# I2C0_1.0 register map
Vendor: Texas Instruments
Peripheral module from a debugger description file (folder mspm0h321x).
Registers are 32-bit, read-write, no defined reset value unless marked. A register's access mark holds for its fields unless they carry their own. Offsets are as the file gives them; lines under a group give offsets from that group; [hi:lo] are bit positions; {n}, {i} and the like mark numbered series; 'fields as' and 'values as' point back to an identical list; <NAME> marks a mode.

## I2C0 (part 1 of 2)
0x800 I2C0_GPRCM group
  0x00 I2C0_PWREN — Power enable
    [0] ENABLE — Enable the power
      0=DISABLE (Disable Power); 1=ENABLE (Enable Power)
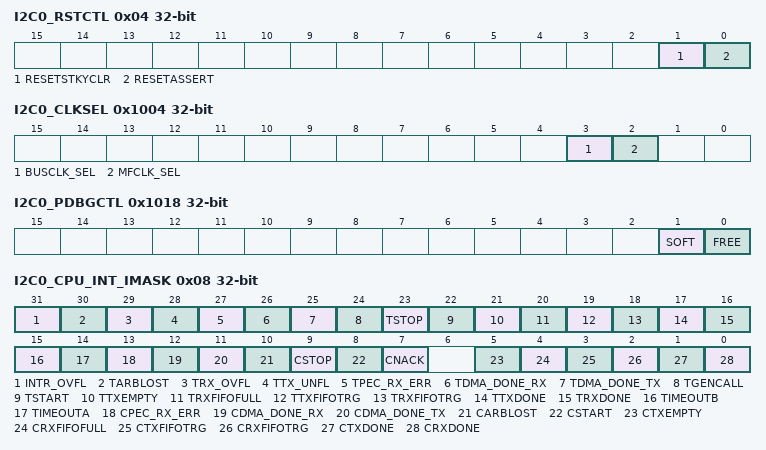
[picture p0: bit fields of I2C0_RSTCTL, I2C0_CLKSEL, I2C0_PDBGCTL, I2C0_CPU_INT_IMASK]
  0x04 I2C0_RSTCTL — Reset Control
    [1] RESETSTKYCLR — Clear the RESETSTKY bit in the STAT register
      0=NOP (Writing 0 has no effect); 1=CLR (Clear reset sticky bit)
    [0] RESETASSERT — Assert reset to the peripheral
      0=NOP (Writing 0 has no effect); 1=ASSERT (Assert reset)
  0x08 I2C0_CLKCFG — Peripheral Clock Configuration Register
    [8] BLOCKASYNC — Async Clock Request is blocked from starting SYSOSC or forcing bus clock to 32MHz
      0=DISABLE (Not block async clock request); 1=ENABLE (Block async clock request)
  0x14 I2C0_STAT ro — Status Register
    [16] RESETSTKY — This bit indicates, if the peripheral was reset, since this bit was cleared by RESETSTKYCLR in the RSTCTL register
      0=NORES (The peripheral has not been reset since this bit was last cleared by RESETSTKYCLR in the RSTCTL register); 1=RESET (The peripheral was reset since the last bit clear)
0x1000 I2C0_CLKDIV — Clock Divider
  [2:0] RATIO — Selects divide ratio of module clock
    0=DIV_BY_1 (Do not divide clock source); {v}=DIV_BY_{v+1} (Divide clock source by {v+1}) (v=1..7)
0x1004 I2C0_CLKSEL — Clock Select for Ultra Low Power peripherals
  [3] BUSCLK_SEL — Selects BUSCLK as clock source if enabled
    0=DISABLE (Does not select this clock as a source); 1=ENABLE (Select this clock as a source)
  [2] MFCLK_SEL — Selects MFCLK as clock source if enabled
    values as BUSCLK_SEL
0x1018 I2C0_PDBGCTL — Peripheral Debug Control
  [1] SOFT — Soft halt boundary control. This function is only available, if [FREE] is set to 'STOP'
    0=IMMEDIATE (The peripheral will halt immediately, even if the resultant state will result in corruption if the system is restarted); 1=DELAYED (The peripheral blocks the debug freeze until it has reached a boundary where it can resume without corruption)
  [0] FREE — Free run control
    0=STOP (The peripheral freezes functionality while the Core Halted input is asserted and resumes when it is deasserted.); 1=RUN (The peripheral ignores the state of the Core Halted input)
0x1020 I2C0_CPU_INT group
  0x00 I2C0_CPU_INT_IIDX ro — Interrupt index
    [7:0] STAT — I2C Module Interrupt Vector Value. This register provides the highes priority interrupt index. A read clears the corresponding interrupt flag in RIS and MISC. 15h-1Fh = Reserved
      0=NO_INTR (No interrupt pending); 1=CRXDONEFG (Controller data received); 2=CTXDONEFG (Controller data transmitted); 3=CRXFIFOTRG (Controller receive FIFO Trigger Level); 4=CTXFIFOTRG (Controller transmit FIFO Trigger level); 5=CRXFIFOFULL (RX FIFO FULL Event/interrupt pending); 6=CTX_EMPTY (Transmit FIFO/Buffer Empty Event/interrupt pending); 8=CNACKFG (Address/Data NACK); 9=CSTARTFG (Start Event); 10=CSTOPFG (Stop Event); 11=CARBLOSTFG (Arbitration Lost); 12=CDMA_DONE_TX (DMA DONE on Channel TX); 13=CDMA_DONE_RX (DMA DONE on Channel RX); 14=CPEC_RX_ERR (Controller PEC Receive Error Event); 15=TIMEOUTA (Timeout A Event); 16=TIMEOUTB (Timeout B Event); 17=TRXDONEFG (Target Data Event); 18=TTXDONEFG (Target Data Event); 19=TRXFIFOTRG (Target receive FIFO Trigger Level); 20=TTXFIFOTRG (Target transmit FIFO Trigger level); 21=TRXFIFOFULL (RX FIFO FULL Event/interrupt pending); 22=TTXEMPTY (Transmit FIFO/Buffer Empty Event/interrupt pending); 23=TSTARTFG (Start Event); 24=TSTOPFG (Stop Event); 25=TGENCALL (General Call Event); 26=TDMA_DONE_TX (DMA DONE on Channel TX); 27=TDMA_DONE_RX (DMA DONE on Channel RX); 28=TPEC_RX_ERR (Target PEC receive error event); 29=TTX_UNFL (Target TX FIFO underflow); 30=TRX_OVFL (Target RX FIFO overflow event); 31=TARBLOST (Target arbitration lost event); 32=INTR_OVFL (Interrupt overflow event)
  0x08 I2C0_CPU_INT_IMASK — Interrupt mask
    [31] INTR_OVFL — Interrupt Overflow Interrupt Mask
      0=CLR (Clear Interrupt Mask); 1=SET (Set Interrupt Mask)
    [30] TARBLOST — Target Arbitration Lost
      0=CLR (Clear Set Interrupt Mask); 1=SET (Set Interrupt Mask)
    [29] TRX_OVFL — Target RX FIFO overflow
      0=CLR (Clear Interrupt Mask); 1=SET (Set Interrupt Mask)
    [28] TTX_UNFL — Target TX FIFO underflow
      0=CLR (Clear Interrupt Mask); 1=SET (Set Interrupt Mask)
    [27] TPEC_RX_ERR — Target RX Pec Error Interrupt
      0=CLR (Clear Interrupt Mask); 1=SET (Set Interrupt Mask)
    [26] TDMA_DONE_RX — Target DMA Done on Event Channel RX
      0=CLR (Clear Interrupt Mask); 1=SET (Set Interrupt Mask)
    [25] TDMA_DONE_TX — Target DMA Done on Event Channel TX
      0=CLR (Clear Interrupt Mask); 1=SET (Set Interrupt Mask)
    [24] TGENCALL — General Call Interrupt
      0=CLR (Clear Interrupt Mask); 1=SET (Set Interrupt Mask)
    [23] TSTOP — Stop Condition Interrupt
      0=CLR (Clear Interrupt Mask); 1=SET (Set Interrupt Mask)
    [22] TSTART — Start Condition Interrupt
      0=CLR (Clear Interrupt Mask); 1=SET (Set Interrupt Mask)
    [21] TTXEMPTY — Target Transmit FIFO Empty interrupt mask. This interrupt is set if all data in the Transmit FIFO have been shifted out and the transmit goes into idle mode.
      0=CLR (Clear Interrupt Mask); 1=SET (Set Interrupt Mask)
    [20] TRXFIFOFULL — RXFIFO full event. This interrupt is set if an Target RX FIFO is full.
      0=CLR (Clear Interrupt Mask); 1=SET (Set Interrupt Mask)
    [19] TTXFIFOTRG — Target Transmit FIFO Trigger
      0=CLR (Clear Interrupt Mask); 1=SET (Set Interrupt Mask)
    [18] TRXFIFOTRG — Target Receive FIFO Trigger
      0=CLR (Clear Interrupt Mask); 1=SET (Set Interrupt Mask)
    [17] TTXDONE — Target Transmit Transaction completed Interrupt
      0=CLR (Clear Interrupt Mask); 1=SET (Set Interrupt Mask)
    [16] TRXDONE — Target Receive Data Interrupt Signals that a byte has been received
      0=CLR (Clear Interrupt Mask); 1=SET (Set Interrupt Mask)
    [15] TIMEOUTB — Timeout B Interrupt
      0=CLR (Clear Interrupt Mask); 1=SET (Set Interrupt Mask)
    [14] TIMEOUTA — Timeout A Interrupt
      0=CLR (Clear Interrupt Mask); 1=SET (Set Interrupt Mask)
    [13] CPEC_RX_ERR — Controller RX Pec Error Interrupt
      0=CLR (Clear Interrupt Mask); 1=SET (Set Interrupt Mask)
    [12] CDMA_DONE_RX — DMA Done on Event Channel RX
      0=CLR (Interrupt disabled); 1=SET (Set Interrupt Mask)
    [11] CDMA_DONE_TX — DMA Done on Event Channel TX
      0=CLR (Interrupt disabled); 1=SET (Set Interrupt Mask)
    [10] CARBLOST — Arbitration Lost Interrupt
      0=CLR (Clear Interrupt Mask); 1=SET (Set Interrupt Mask)
    [9] CSTOP — STOP Detection Interrupt
      0=CLR (Clear Interrupt Mask); 1=SET (Set Interrupt Mask)
    [8] CSTART — START Detection Interrupt
      0=CLR (Clear Interrupt Mask); 1=SET (Set Interrupt Mask)
    [7] CNACK — Address/Data NACK Interrupt
      0=CLR (Clear Interrupt Mask); 1=SET (Set Interrupt Mask)
    [5] CTXEMPTY — Transmit FIFO Empty interrupt mask. This interrupt is set if all data in the Transmit FIFO have been shifted out and the transmit goes into idle mode.
      0=CLR (Clear Interrupt Mask); 1=SET (Set Interrupt Mask)
    [4] CRXFIFOFULL — RXFIFO full event. This interrupt is set if an RX FIFO is full.
      0=CLR (Clear Interrupt Mask); 1=SET (Set Interrupt Mask)
    [3] CTXFIFOTRG — Controller Transmit FIFO Trigger Trigger when Transmit FIFO contains <= defined bytes
      0=CLR (Clear Interrupt Mask); 1=SET (Set Interrupt Mask)
    [2] CRXFIFOTRG — Controller Receive FIFO Trigger Trigger when RX FIFO contains >= defined bytes
      0=CLR (Clear Interrupt Mask); 1=SET (Set Interrupt Mask)
    [1] CTXDONE — Controller Transmit Transaction completed Interrupt
      0=CLR (Clear Interrupt Mask); 1=SET (Set Interrupt Mask)
    [0] CRXDONE — Controller Receive Transaction completed Interrupt
      0=CLR (Clear Interrupt Mask); 1=SET (Set Interrupt Mask)
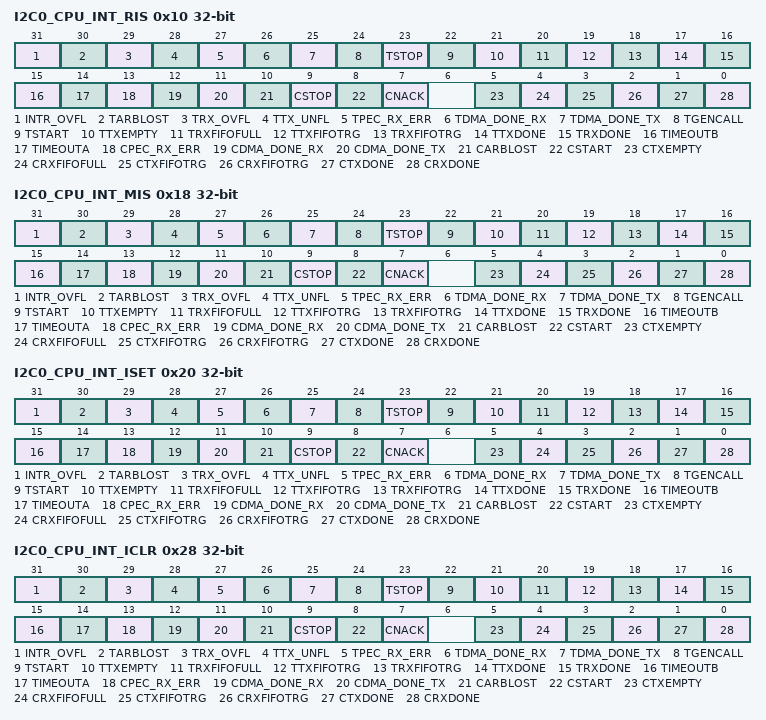
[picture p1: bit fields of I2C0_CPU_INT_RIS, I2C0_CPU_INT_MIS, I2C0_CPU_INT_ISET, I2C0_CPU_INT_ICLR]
  0x10 I2C0_CPU_INT_RIS — Raw interrupt status
    [31] INTR_OVFL — Interrupt overflow interrupt It is set when CSTART or CSTOP interrupts overflow i.e. occur twice without being serviced
      0=CLR (Interrupt did not occur); 1=SET (Interrupt occured)
    [30] TARBLOST — Target Arbitration Lost
      0=CLR (Interrupt did not occur); 1=SET (Interrupt occured)
    [29] TRX_OVFL — Target RX FIFO overflow
      0=CLR (Interrupt did not occur); 1=SET (Interrupt Occured)
    [28] TTX_UNFL — Target TX FIFO underflow
      0=CLR (Interrupt did not occur); 1=SET (Interrupt occured)
    [27] TPEC_RX_ERR — Target RX Pec Error Interrupt
      0=CLR (Interrupt did not occur); 1=SET (Interrupt ocuured)
    [26] TDMA_DONE_RX — DMA Done on Event Channel RX
      0=CLR (Clear interrupt); 1=SET (Set interrupt)
    [25] TDMA_DONE_TX — DMA Done on Event Channel TX
      0=CLR (Clear interrupt); 1=SET (Set interrupt)
    [24] TGENCALL — General Call Interrupt
      0=CLR (Clear Interrupt Mask); 1=SET (Interrupt occured)
    [23] TSTOP — Stop Condition Interrupt
      0=CLR (Clear Interrupt); 1=SET (Set interrupt)
    [22] TSTART — Start Condition Interrupt
      0=CLR (Clear interrupt); 1=SET (Set Interrupt)
    [21] TTXEMPTY — Transmit FIFO Empty interrupt mask. This interrupt is set if all data in the Transmit FIFO have been shifted out and the transmit goes into idle mode.
      0=CLR (Interrupt did not occur); 1=SET (Interrupt occured)
    [20] TRXFIFOFULL — RXFIFO full event. This interrupt is set if an RX FIFO is full.
      0=CLR (Clear Interrupt Mask); 1=SET (Interrupt occured)
    [19] TTXFIFOTRG — Target Transmit FIFO Trigger
      0=CLR (Clear Interrupt Mask); 1=SET (Interrupt occured)
    [18] TRXFIFOTRG — Target Receive FIFO Trigger
      0=CLR (Clear Interrupt Mask); 1=SET (Interrupt occured)
    [17] TTXDONE — Target Transmit Transaction completed Interrupt
      0=CLR (Interrupt did not occur); 1=SET (Interrupt occured)
    [16] TRXDONE — Target Receive Data Interrupt Signals that a byte has been received
      0=CLR (Interrupt did not occur); 1=SET (Interrupt occured)
    [15] TIMEOUTB — Timeout B Interrupt
      0=CLR (Interrupt did not occur); 1=SET (Interrupt occured)
    [14] TIMEOUTA — Timeout A Interrupt
      0=CLR (Interrupt did not occur); 1=SET (Interrupt occured)
    [13] CPEC_RX_ERR — Controller RX Pec Error Interrupt
      0=CLR (Interrupt did not occur); 1=SET (Interrupt Occured)
    [12] CDMA_DONE_RX — DMA Done on Event Channel RX
      0=CLR (Interrupt disabled); 1=SET (Interrupt occured)
    [11] CDMA_DONE_TX — DMA Done on Event Channel TX
      0=CLR (Interrupt disabled); 1=SET (Interrupt occured)
    [10] CARBLOST — Arbitration Lost Interrupt
      0=CLR (Interrupt did not occur); 1=SET (Interrupt occured)
    [9] CSTOP — STOP Detection Interrupt
      0=CLR (Interrupt did not occur); 1=SET (Interrupt occured)
    [8] CSTART — START Detection Interrupt
      0=CLR (Interrupt did not occur); 1=SET (Interrupt occured)
    [7] CNACK — Address/Data NACK Interrupt
      0=CLR (Interrupt did not occur); 1=SET (Interrupt occured)
    [5] CTXEMPTY — Transmit FIFO Empty interrupt mask. This interrupt is set if all data in the Transmit FIFO have been shifted out and the transmit goes into idle mode.
      0=CLR (Interrupt did not occur); 1=SET (Interrupt occured)
    [4] CRXFIFOFULL — RXFIFO full event. This interrupt is set if an RX FIFO is full.
      0=CLR (Interrupt did not occur); 1=SET (Interrupt occured)
    [3] CTXFIFOTRG — Controller Transmit FIFO Trigger Trigger when Transmit FIFO contains <= defined bytes
      0=CLR (Clear Interrupt Mask); 1=SET (Interrupt occured)
    [2] CRXFIFOTRG — Controller Receive FIFO Trigger Trigger when RX FIFO contains >= defined bytes
      0=CLR (Clear Interrupt Mask); 1=SET (Interrupt occured)
    [1] CTXDONE — Controller Transmit Transaction completed Interrupt
      0=CLR (Interrupt did not occur); 1=SET (Interrupt occured)
    [0] CRXDONE — Controller Receive Transaction completed Interrupt
      0=CLR (Interrupt did not occur); 1=SET (Interrupt occured)
  0x18 I2C0_CPU_INT_MIS — Masked interrupt status
    [31] INTR_OVFL — Interrupt overflow
      0=CLR (Interrupt did not occur); 1=SET (Interrupt occured)
    [30] TARBLOST — Target Arbitration Lost
      0=CLR (Clear interrupt mask); 1=SET (Set interrupt mask)
    [29] TRX_OVFL — Target RX FIFO overflow
      0=CLR (Clear interrupt mask); 1=SET (Set interrupt mask)
    [28] TTX_UNFL — Target TX FIFO underflow
      0=CLR (Clear interrupt mask); 1=SET (Set interrupt mask)
    [27] TPEC_RX_ERR — Target RX Pec Error Interrupt
      0=CLR (Clear interrupt mask); 1=SET (Set interrupt mask)
    [26] TDMA_DONE_RX — DMA Done on Event Channel RX
      0=CLR (Clear MIS); 1=SET (Set MIS)
    [25] TDMA_DONE_TX — DMA Done on Event Channel TX
      0=CLR (Clear MIS); 1=SET (Set MIS)
    [24] TGENCALL — General Call Interrupt
      0=CLR (Interrupt did not occur); 1=SET (Interrupt occured)
    [23] TSTOP — Target STOP Detection Interrupt
      0=CLR (Clear MIS); 1=SET (Set MIS)
    [22] TSTART — Target START Detection Interrupt
      0=CLR (Clear MIS); 1=SET (Set MIS)
    [21] TTXEMPTY — Transmit FIFO Empty interrupt mask. This interrupt is set if all data in the Transmit FIFO have been shifted out and the transmit goes into idle mode.
      0=CLR (Interrupt did not occur); 1=SET (Interrupt occured)
    [20] TRXFIFOFULL — RXFIFO full event. This interrupt is set if an RX FIFO is full.
      0=CLR (Clear Interrupt Mask); 1=SET (Interrupt occured)
    [19] TTXFIFOTRG — Target Transmit FIFO Trigger
      0=CLR (Clear Interrupt Mask); 1=SET (Interrupt occured)
    [18] TRXFIFOTRG — Target Receive FIFO Trigger
      0=CLR (Clear Interrupt Mask); 1=SET (Interrupt occured)
    [17] TTXDONE — Target Transmit Transaction completed Interrupt
      0=CLR (Interrupt did not occur); 1=SET (Interrupt occured)
    [16] TRXDONE — Target Receive Data Interrupt Signals that a byte has been received
      0=CLR (Interrupt did not occur); 1=SET (Interrupt occured)
    [15] TIMEOUTB — Timeout B Interrupt
      0=CLR (Clear interrupt mask); 1=SET (Set interrupt mask)
    [14] TIMEOUTA — Timeout A Interrupt
      0=CLR (Interrupt did not occur); 1=SET (Interrupt occured)
    [13] CPEC_RX_ERR — Controller RX Pec Error Interrupt
      0=CLR (Clear interrupt mask); 1=SET (Set interrupt mask)
    [12] CDMA_DONE_RX — DMA Done on Event Channel RX
      0=CLR (Interrupt disabled); 1=SET (Interrupt occured)
    [11] CDMA_DONE_TX — DMA Done on Event Channel TX
      0=CLR (Interrupt disabled); 1=SET (Interrupt occured)
    [10] CARBLOST — Arbitration Lost Interrupt
      0=CLR (Interrupt did not occur); 1=SET (Interrupt occured)
    [9] CSTOP — STOP Detection Interrupt
      0=CLR (Interrupt did not occur); 1=SET (Interrupt occured)
    [8] CSTART — START Detection Interrupt
      0=CLR (Interrupt did not occur); 1=SET (Interrupt occured)
    [7] CNACK — Address/Data NACK Interrupt
      0=CLR (Interrupt did not occur); 1=SET (Interrupt occured)
    [5] CTXEMPTY — Transmit FIFO Empty interrupt mask. This interrupt is set if all data in the Transmit FIFO have been shifted out and the transmit goes into idle mode.
      0=CLR (Interrupt did not occur); 1=SET (Interrupt occured)
    [4] CRXFIFOFULL — RXFIFO full event. This interrupt is set if the RX FIFO is full.
      0=CLR (Interrupt did not occur); 1=SET (Interrupt occured)
    [3] CTXFIFOTRG — Controller Transmit FIFO Trigger Trigger when Transmit FIFO contains <= defined bytes
      0=CLR (Clear Interrupt Mask); 1=SET (Interrupt occured)
    [2] CRXFIFOTRG — Controller Receive FIFO Trigger Trigger when RX FIFO contains >= defined bytes
      0=CLR (Clear Interrupt Mask); 1=SET (Interrupt occured)
    [1] CTXDONE — Controller Transmit Transaction completed Interrupt
      0=CLR (Interrupt did not occur); 1=SET (Interrupt occured)
    [0] CRXDONE — Controller Receive Data Interrupt
      0=CLR (Interrupt did not occur); 1=SET (Interrupt occured)
  0x20 I2C0_CPU_INT_ISET — Interrupt set
    [31] INTR_OVFL — Interrupt overflow
      0=NO_EFFECT; 1=SET (Set interrupt)
    [30] TARBLOST — Target Arbitration Lost
      0=NO_EFFECT (Writing 0 has no effect); 1=SET (Set interrupt)
    [29] TRX_OVFL — Target RX FIFO overflow
      0=NO_EFFECT (Writing 0 has no effect); 1=SET (Set interrupt)
    [28] TTX_UNFL — Target TX FIFO underflow
      0=NO_EFFECT (Writing 0 has no effect); 1=SET (Set interrupt)
    [27] TPEC_RX_ERR — Target RX Pec Error Interrupt
      0=NO_EFFECT (Writing 0 has no effect); 1=SET (Set interrupt)
    [26] TDMA_DONE_RX — DMA Done on Event Channel RX
      0=NO_EFFECT (Writing 0 has no effect); 1=SET (Set interrupt)
    [25] TDMA_DONE_TX — DMA Done on Event Channel TX
      0=NO_EFFECT (Writing 0 has no effect); 1=SET (Set interrupt)
    [24] TGENCALL — General Call Interrupt
      0=NO_EFFECT (Writing 0 has no effect); 1=SET (Set Interrupt)
    [23] TSTOP — Stop Condition Interrupt
      0=NO_EFFECT (Writing 0 has no effect); 1=SET (Set interrupt)
    [22] TSTART — Start Condition Interrupt
      0=NO_EFFECT (Writing 0 has no effect); 1=SET (Set interrupt)
    [21] TTXEMPTY — Transmit FIFO Empty interrupt mask. This interrupt is set if all data in the Transmit FIFO have been shifted out and the transmit goes into idle mode.
      0=NO_EFFECT (Writing 0 has no effect); 1=SET (Set Interrupt)
    [20] TRXFIFOFULL — RXFIFO full event. This interrupt is set if an RX FIFO is full.
      0=NO_EFFECT (Clear Interrupt Mask); 1=SET (Set Interrupt)
    [19] TTXFIFOTRG — Target Transmit FIFO Trigger
      0=NO_EFFECT (Clear Interrupt Mask); 1=SET (Set Interrupt)
    [18] TRXFIFOTRG — Target Receive FIFO Trigger
      0=NO_EFFECT (Clear Interrupt Mask); 1=SET (Set Interrupt)
    [17] TTXDONE — Target Transmit Transaction completed Interrupt
      0=NO_EFFECT (Writing 0 has no effect); 1=SET (Set Interrupt)
    [16] TRXDONE — Target Receive Data Interrupt Signals that a byte has been received
      0=NO_EFFECT (Writing 0 has no effect); 1=SET (Set Interrupt)
    [15] TIMEOUTB — Timeout B Interrupt
      0=NO_EFFECT (Writing 0 has no effect); 1=SET (Set interrupt)
    [14] TIMEOUTA — Timeout A interrupt
      0=NO_EFFECT (Writing 0 has no effect); 1=SET (Set Interrupt)
    [13] CPEC_RX_ERR — Controller RX Pec Error Interrupt
      0=NO_EFFECT (Writing 0 has no effect); 1=SET (Set interrupt)
    [12] CDMA_DONE_RX — DMA Done on Event Channel RX
      0=NO_EFFECT (Interrupt disabled); 1=SET (Set Interrupt)
    [11] CDMA_DONE_TX — DMA Done on Event Channel TX
      0=NO_EFFECT (Interrupt disabled); 1=SET (Set Interrupt)
    [10] CARBLOST — Arbitration Lost Interrupt
      0=NO_EFFECT (Writing 0 has no effect); 1=SET (Set Interrupt)
    [9] CSTOP — STOP Detection Interrupt
      0=NO_EFFECT (Writing 0 has no effect); 1=SET (Set Interrupt)
    [8] CSTART — START Detection Interrupt
      0=NO_EFFECT (Writing 0 has no effect); 1=SET (Set Interrupt)
    [7] CNACK — Address/Data NACK Interrupt
      0=NO_EFFECT (Writing 0 has no effect); 1=SET (Set Interrupt)
    [5] CTXEMPTY — Transmit FIFO Empty interrupt mask. This interrupt is set if all data in the Transmit FIFO have been shifted out and the transmit goes into idle mode.
      0=NO_EFFECT (Writing 0 has no effect); 1=SET (Set Interrupt)
    [4] CRXFIFOFULL — RXFIFO full event.
      0=NO_EFFECT (Writing 0 has no effect); 1=SET (Set Interrupt)
    [3] CTXFIFOTRG — Controller Transmit FIFO Trigger Trigger when Transmit FIFO contains <= defined bytes
      0=NO_EFFECT (Clear Interrupt Mask); 1=SET (Set Interrupt)
    [2] CRXFIFOTRG — Controller Receive FIFO Trigger Trigger when RX FIFO contains >= defined bytes
      0=NO_EFFECT (Clear Interrupt Mask); 1=SET (Set Interrupt)
    [1] CTXDONE — Controller Transmit Transaction completed Interrupt
      0=NO_EFFECT (Writing 0 has no effect); 1=SET (Set Interrupt)
    [0] CRXDONE — Controller Receive Data Interrupt Signals that a byte has been received
      0=NO_EFFECT (Writing 0 has no effect); 1=SET (Set Interrupt)
  0x28 I2C0_CPU_INT_ICLR — Interrupt clear
    [31] INTR_OVFL — Interrupt overflow
      0=NO_EFFECT; 1=CLR (Clear interrupt)
    [30] TARBLOST — Target Arbitration Lost
      0=NO_EFFECT (Writing 0 has no effect); 1=CLR (Clear Interrupt)
    [29] TRX_OVFL — Target RX FIFO overflow
      values as TARBLOST
    [28] TTX_UNFL — Target TX FIFO underflow
      values as TARBLOST
    [27] TPEC_RX_ERR — Target RX Pec Error Interrupt
      values as TARBLOST
    [26] TDMA_DONE_RX — DMA Done on Event Channel RX
      0=NO_EFFECT (Writing 0 has no effect); 1=CLR (Clear interrupt)
    [25] TDMA_DONE_TX — DMA Done on Event Channel TX
      values as TDMA_DONE_RX
    [24] TGENCALL — General Call Interrupt
      values as TARBLOST
    [23] TSTOP — Target STOP Detection Interrupt
      values as TDMA_DONE_RX
    [22] TSTART — Target START Detection Interrupt
      values as TDMA_DONE_RX
    [21] TTXEMPTY — Transmit FIFO Empty interrupt mask. This interrupt is set if all data in the Transmit FIFO have been shifted out and the transmit goes into idle mode.
      values as TARBLOST
    [20] TRXFIFOFULL — RXFIFO full event. This interrupt is set if an RX FIFO is full.
      0=NO_EFFECT (Clear Interrupt Mask); 1=CLR (Clear Interrupt)
    [19] TTXFIFOTRG — Target Transmit FIFO Trigger
      0=NO_EFFECT (Clear Interrupt Mask); 1=CLR (Clear Interrupt)
    [18] TRXFIFOTRG — Target Receive FIFO Trigger
      0=NO_EFFECT (Clear Interrupt Mask); 1=CLR (Clear Interrupt)
    [17] TTXDONE — Target Transmit Transaction completed Interrupt
      values as TARBLOST
    [16] TRXDONE — Target Receive Data Interrupt Signals that a byte has been received
      values as TARBLOST
    [15] TIMEOUTB — Timeout B Interrupt
      values as TARBLOST
    [14] TIMEOUTA — Timeout A interrupt
      values as TARBLOST
    [13] CPEC_RX_ERR — Controller RX Pec Error Interrupt
      values as TARBLOST
    [12] CDMA_DONE_RX — DMA Done on Event Channel RX
      0=NO_EFFECT (Interrupt disabled); 1=CLR (Clear Interrupt)
    [11] CDMA_DONE_TX — DMA Done on Event Channel TX
      0=NO_EFFECT (Interrupt disabled); 1=CLR (Clear Interrupt)
    [10] CARBLOST — Arbitration Lost Interrupt
      values as TARBLOST
    [9] CSTOP — STOP Detection Interrupt
      values as TARBLOST
    [8] CSTART — START Detection Interrupt
      values as TARBLOST
    [7] CNACK — Address/Data NACK Interrupt
      values as TARBLOST
    [5] CTXEMPTY — Transmit FIFO Empty interrupt mask. This interrupt is set if all data in the Transmit FIFO have been shifted out and the transmit goes into idle mode.
      values as TARBLOST
    [4] CRXFIFOFULL — RXFIFO full event.
      values as TARBLOST
    [3] CTXFIFOTRG — Controller Transmit FIFO Trigger Trigger when Transmit FIFO contains <= defined bytes
      0=NO_EFFECT (Clear Interrupt Mask); 1=CLR (Clear Interrupt)
    [2] CRXFIFOTRG — Controller Receive FIFO Trigger Trigger when RX FIFO contains >= defined bytes
      0=NO_EFFECT (Clear Interrupt Mask); 1=CLR (Clear Interrupt)
    [1] CTXDONE — Controller Transmit Transaction completed Interrupt
      values as TARBLOST
    [0] CRXDONE — Controller Receive Data Interrupt Signals that a byte has been received
      values as TARBLOST
0x1050 I2C0_DMA_TRIG1 group
  0x00 I2C0_DMA_TRIG1_IIDX ro — Interrupt index
    [7:0] STAT — I2C Module Interrupt Vector Value. This register provides the highes priority interrupt index. A read clears the corresponding interrupt flag in RIS and MISC. 15h-1Fh = Reserved
      0=NO_INTR (No interrupt pending); 1=CRXFIFOTRG (Controller receive FIFO Trigger Level); 2=CTXFIFOTRG (Controller transmit FIFO Trigger level); 3=TRXFIFOTRG (Target receive FIFO Trigger Level); 4=TTXFIFOTRG (Target transmit FIFO Trigger level)
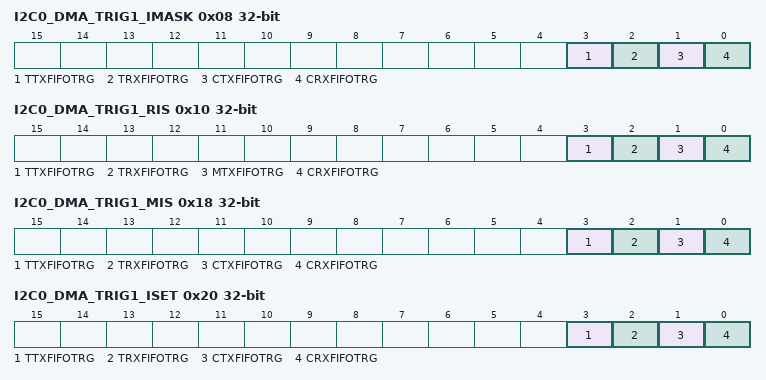
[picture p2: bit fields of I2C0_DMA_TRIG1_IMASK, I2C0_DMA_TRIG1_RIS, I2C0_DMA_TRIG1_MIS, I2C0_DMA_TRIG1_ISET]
  0x08 I2C0_DMA_TRIG1_IMASK — Interrupt mask
    [all] fields
      0=CLR (Clear Interrupt Mask); 1=SET (Set Interrupt Mask)
    [3] TTXFIFOTRG — Target Transmit FIFO Trigger
    [2] TRXFIFOTRG — Target Receive FIFO Trigger
    [1] CTXFIFOTRG — Controller Transmit FIFO Trigger Trigger when Transmit FIFO contains <= defined bytes
    [0] CRXFIFOTRG — Controller Receive FIFO Trigger Trigger when RX FIFO contains >= defined bytes
  0x10 I2C0_DMA_TRIG1_RIS — Raw interrupt status
    [all] fields
      0=CLR (Clear Interrupt Mask); 1=SET (Set Interrupt Mask)
    [3] TTXFIFOTRG — Target Transmit FIFO Trigger
    [2] TRXFIFOTRG — Target Receive FIFO Trigger
    [1] MTXFIFOTRG — Controller Transmit FIFO Trigger Trigger when Transmit FIFO contains <= defined bytes
    [0] CRXFIFOTRG — Controller Receive FIFO Trigger Trigger when RX FIFO contains >= defined bytes
  0x18 I2C0_DMA_TRIG1_MIS — Masked interrupt status
    fields as I2C0_DMA_TRIG1.I2C0_DMA_TRIG1_IMASK
  0x20 I2C0_DMA_TRIG1_ISET — Interrupt set
    [all] fields
      0=NO_EFFECT (Clear Interrupt Mask); 1=SET (Set Interrupt Mask)
    [3] TTXFIFOTRG — Target Transmit FIFO Trigger
    [2] TRXFIFOTRG — Target Receive FIFO Trigger
    [1] CTXFIFOTRG — Controller Transmit FIFO Trigger Trigger when Transmit FIFO contains <= defined bytes
    [0] CRXFIFOTRG — Controller Receive FIFO Trigger Trigger when RX FIFO contains >= defined bytes
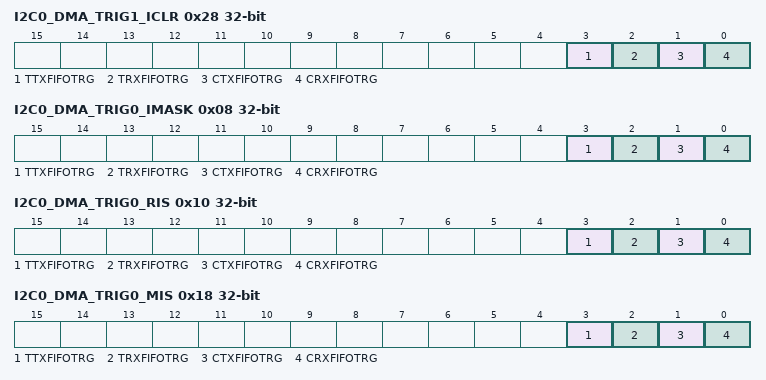
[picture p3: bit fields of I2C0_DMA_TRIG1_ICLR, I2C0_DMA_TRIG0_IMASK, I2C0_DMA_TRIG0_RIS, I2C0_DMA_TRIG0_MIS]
  0x28 I2C0_DMA_TRIG1_ICLR — Interrupt clear
    [all] fields
      0=NO_EFFECT (Clear Interrupt Mask); 1=CLR (Set Interrupt Mask)
    [3] TTXFIFOTRG — Target Transmit FIFO Trigger
    [2] TRXFIFOTRG — Target Receive FIFO Trigger
    [1] CTXFIFOTRG — Controller Transmit FIFO Trigger Trigger when Transmit FIFO contains <= defined bytes
    [0] CRXFIFOTRG — Controller Receive FIFO Trigger Trigger when RX FIFO contains >= defined bytes
0x1080 I2C0_DMA_TRIG0 group
  0x00 I2C0_DMA_TRIG0_IIDX ro — Interrupt index
    fields as I2C0_DMA_TRIG1.I2C0_DMA_TRIG1_IIDX
  0x08 I2C0_DMA_TRIG0_IMASK — Interrupt mask
    fields as I2C0_DMA_TRIG1.I2C0_DMA_TRIG1_IMASK
  0x10 I2C0_DMA_TRIG0_RIS — Raw interrupt status
    fields as I2C0_DMA_TRIG1.I2C0_DMA_TRIG1_IMASK
  0x18 I2C0_DMA_TRIG0_MIS — Masked interrupt status
    fields as I2C0_DMA_TRIG1.I2C0_DMA_TRIG1_IMASK
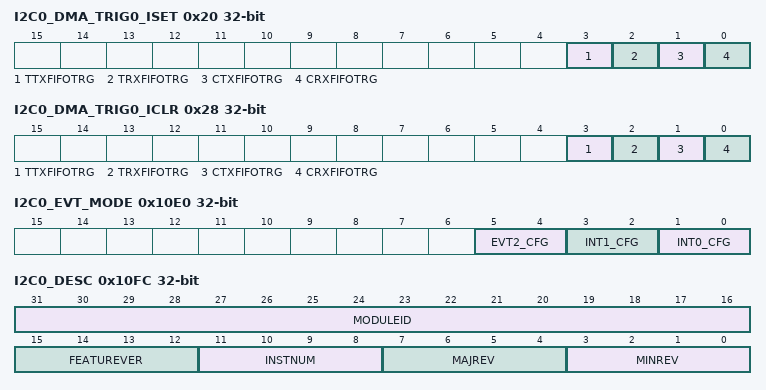
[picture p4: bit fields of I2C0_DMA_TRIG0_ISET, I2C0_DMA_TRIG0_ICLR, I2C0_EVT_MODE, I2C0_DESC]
  0x20 I2C0_DMA_TRIG0_ISET — Interrupt set
    fields as I2C0_DMA_TRIG1.I2C0_DMA_TRIG1_ISET
  0x28 I2C0_DMA_TRIG0_ICLR — Interrupt clear
    fields as I2C0_DMA_TRIG1.I2C0_DMA_TRIG1_ICLR
0x10E0 I2C0_EVT_MODE ro — Event Mode
  [all] fields
    0=DISABLE (The interrupt or event line is disabled.); 1=SOFTWARE (The interrupt or event line is in software mode. Software must clear the RIS.); 2=HARDWARE (The interrupt or event line is in hardware mode. The hardware (another module) clears automatically the associated RIS flag.)
  [5:4] EVT2_CFG — Event line mode select for event corresponding to [IPSTANDARD.DMA_TRIG0]
  [3:2] INT1_CFG — Event line mode select for event corresponding to [IPSTANDARD.DMA_TRIG1]
  [1:0] INT0_CFG — Event line mode select for event corresponding to [IPSTANDARD.CPU_INT]
0x10E4 I2C0_INTCTL — Interrupt control register
  [0] INTEVAL — Writing a 1 to this field re-evaluates the interrupt sources.
    0=DISABLE (The interrupt or event line is disabled.); 1=EVAL (The interrupt or event line is in software mode. Software must clear the RIS.)
0x10FC I2C0_DESC — Module Description
  [31:16] MODULEID — Module identification contains a unique peripheral identification number. The assignments are maintained in a central database for all of the platform modules to ensure uniqueness.
    0=MINIMUM (Smallest value); 0xFFFF=MAXIMUM (Highest possible value)
  [15:12] FEATUREVER — Feature Set for the module *instance*
    0=MINIMUM (Smallest value); 15=MAXIMUM (Highest possible value)
  [11:8] INSTNUM — Instance Number within the device. This will be a parameter to the RTL for modules that can have multiple instances
    values as FEATUREVER
  [7:4] MAJREV — Major rev of the IP
    values as FEATUREVER
  [3:0] MINREV — Minor rev of the IP
    values as FEATUREVER
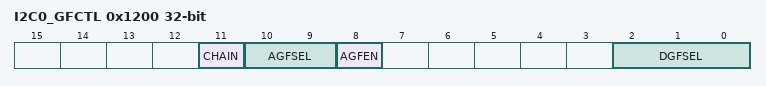
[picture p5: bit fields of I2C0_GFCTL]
0x1200 I2C0_GFCTL — I2C Glitch Filter Control
  [11] CHAIN — Analog and digital noise filters chaining enable.
    0=DISABLE (When 0, chaining is disabled and only digital filter output is available to IP logic for oversampling); 1=ENABLE (When 1, analog and digital glitch filters are chained and the output of the combination is made available to IP logic for oversampling)
  [10:9] AGFSEL — Analog Glitch Suppression Pulse Width This field controls the pulse width select for the analog glitch suppression on SCL and SDA lines. See device datasheet for exact values. (ULP I2C only)
    0=AGLIT_5 (Pulses shorter then 5ns length are filtered.); 1=AGLIT_10 (Pulses shorter then 10ns length are filtered.); 2=AGLIT_25 (Pulses shorter then 25ns length are filtered.); 3=AGLIT_50 (Pulses shorter then 50ns length are filtered.)
  [8] AGFEN — Analog Glitch Suppression Enable
    0=DISABLE (Analog Glitch Filter disable); 1=ENABLE (Analog Glitch Filter enable)
  [2:0] DGFSEL — Glitch Suppression Pulse Width This field controls the pulse width select for glitch suppression on the SCL and SDA lines. The following values are the glitch suppression values in terms of functional clocks. (Core Domain only)
    0=DISABLED (Bypass); 1=CLK_1 (1 clock); 2=CLK_2 (2 clocks); 3=CLK_3 (3 clocks); 4=CLK_4 (4 clocks); 5=CLK_8 (8 clocks); 6=CLK_16 (16 clocks); 7=CLK_31 (31 clocks)
